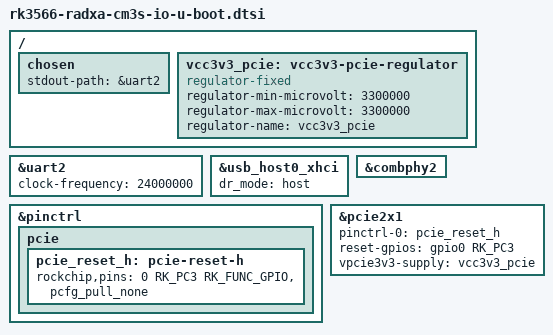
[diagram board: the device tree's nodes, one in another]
// SPDX-License-Identifier: (GPL-2.0+ OR MIT)
/*
 * Copyright (c) 2023 Radxa Limited
 */

#include "rk356x-u-boot.dtsi"

/ {
	chosen {
		stdout-path = &uart2;
	};

	vcc3v3_pcie: vcc3v3-pcie-regulator {
		compatible = "regulator-fixed";
		regulator-min-microvolt = <3300000>;
		regulator-max-microvolt = <3300000>;
		regulator-name = "vcc3v3_pcie";
	};
};

&uart2 {
	clock-frequency = <24000000>;
	bootph-all;
	status = "okay";
};

&usb_host0_xhci {
	dr_mode ="host";
};

&combphy2 {
	status = "okay";
};

&pinctrl {
	pcie {
		pcie_reset_h: pcie-reset-h {
			rockchip,pins = <0 RK_PC3 RK_FUNC_GPIO &pcfg_pull_none>;
		};
	};
};

&pcie2x1 {
	pinctrl-names = "default";
	pinctrl-0 = <&pcie_reset_h>;
	reset-gpios = <&gpio0 RK_PC3 GPIO_ACTIVE_HIGH>;
	vpcie3v3-supply = <&vcc3v3_pcie>;
	status = "okay";
};
